AUTOSAR XML (schema 00051)
package /TPC_Composition/Components
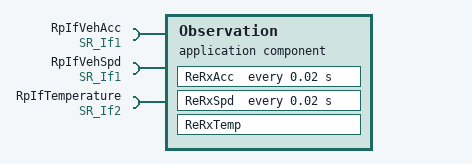
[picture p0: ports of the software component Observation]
  application sw component type Observation
    require port RpIfVehAcc: required-interface=SR_If1, nonqueued-receiver-com-spec{data-element=Acc, init-value=777}
    require port RpIfVehSpd: required-interface=SR_If1, nonqueued-receiver-com-spec{data-element=Spd, init-value=666}
    require port RpIfTemperature: required-interface=SR_If2, queued-receiver-com-spec=Temp
    behavior SWC_Observation_InternalBehavior: supports-multiple-instantiation=true
      runnable ReRxAcc
        data-receive-point-by-arguments:
          access DataReceivePointByArgument_PpIfVehMov_Acc: accessed-variable=RpIfVehAcc.Acc
      runnable ReRxSpd
        data-receive-point-by-values:
          access DataReceivePointByValue_PpIfVehMov_Spd: accessed-variable=RpIfVehSpd.Spd
      runnable ReRxTemp
        data-receive-point-by-values:
          access DataReceivePointByValue_PpIfTemperature_Temp: accessed-variable=RpIfTemperature.Temp
        wait point ReRxTemp_WaitPoint: trigger=Obv_Ev_DR
      timing event EvTiAcc_20ms: start-on-event=ReRxAcc, period=0.02
      timing event EvTiSpd_20ms: start-on-event=ReRxSpd, period=0.02
      data received event Obv_Ev_DR: data=RpIfTemperature.Temp, start-on-event=ReRxTemp
      port-api-options:
        port=RpIfVehAcc, transformer-status-forwarding=TRANSFORMER-STATUS-FORWARDING, error-handling=TRANSFORMER-ERROR-HANDLING
        port=RpIfVehSpd, error-handling=NO-TRANSFORMER-ERROR-HANDLING
        port=RpIfTemperature, error-handling=TRANSFORMER-ERROR-HANDLING
